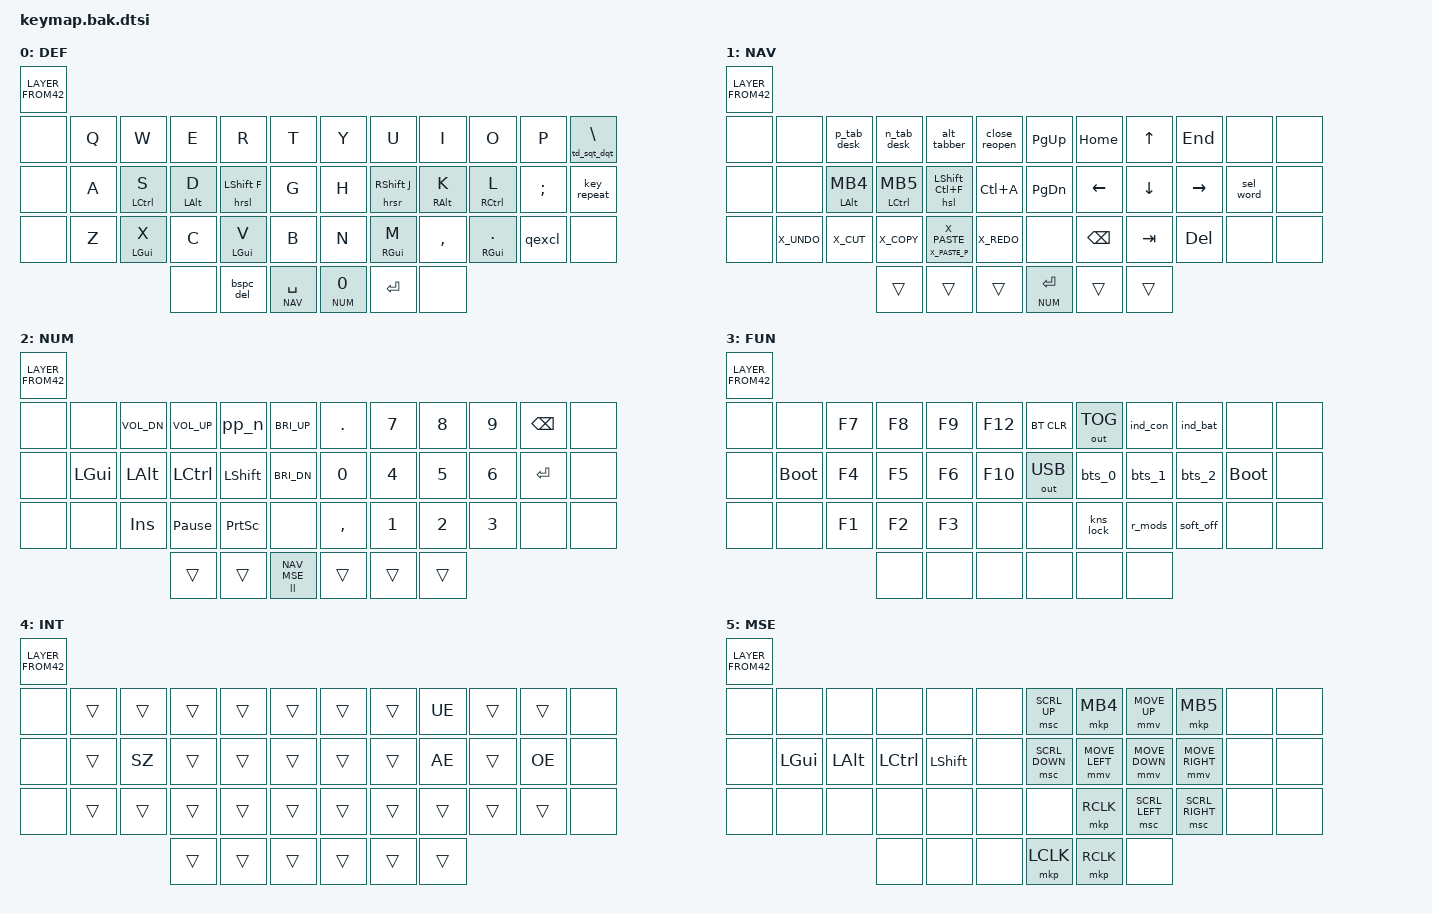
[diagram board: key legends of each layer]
/*
 * Copyright (c) 2020 The ZMK Contributors
 *
 * SPDX-License-Identifier: MIT
 */

#include <dt-bindings/zmk/bt.h>
#include <dt-bindings/zmk/keys.h>
#include <dt-bindings/zmk/mouse.h>
#include <dt-bindings/zmk/outputs.h>

#ifndef KEYMAP_DRAWER
#include "include/keys_de.h"
#endif

#define DEF 0
#define NAV 1
#define NUM 2
#define FUN 3
#define INT 4
#define MSE 5

#define CT(KEY) &mt LC(KEY) KEY

#define MEH     LC(LS(LALT))
#define HYPER   LC(LS(LA(LGUI)))

#define X_REDO   LC(Y)
#define X_PASTE   LC(V)
#define X_PASTE_P LS(LC(V))
#define X_COPY   LC(C)
#define X_CUT   LC(X)
#define X_UNDO   LC(Z)

#include "include/keypos.h"
#include "behaviors.dtsi"
#include "combos.dtsi"
#include "macros.dtsi"
#include "mouse.dtsi"

/ {
    conditional_layers {
        compatible = "zmk,conditional-layers";

        tri_layer  {
            if-layers = <NAV NUM>;
            then-layer = <FUN>;
        };
    };

    keymap {
        compatible = "zmk,keymap";

        default_layer {
            display-name = "DEF";
            bindings = <LAYER_FROM42( \
// ┌─────────────────┬─────────────────┬─────────────────┬─────────────────┬─────────────────┬─────────────────╥─────────────────┬─────────────────┬─────────────────┬─────────────────┬─────────────────┬─────────────────┐
    &none,            &kp Q,            &kp W,            &kp E,            &kp R,            &kp T,            &kp Y,            &kp U,            &kp I,            &kp O,            &kp P,            &td_sqt_dqt,     \
// ├─────────────────┼─────────────────┼─────────────────┼─────────────────┼─────────────────┼─────────────────╫─────────────────┼─────────────────┼─────────────────┼─────────────────┼─────────────────┼─────────────────┤
    &none,            &kp A,            &hrml LCTL S,     &hrml LALT D,     &hrsl LSHIFT F,  &kp G,             &kp H,            &hrsr RSHFT J,    &hrmr RALT K,    &hrmr RCTRL L,   &kp SEMI,         &key_repeat,     \
// ├─────────────────┼─────────────────┼─────────────────┼─────────────────┼─────────────────┼─────────────────╫─────────────────┼─────────────────┼─────────────────┼─────────────────┼─────────────────┼─────────────────┤
    &none,            &kp Z,            &hrml LGUI X,     &kp C,            &hrml LGUI V,    &kp B,             &kp N,            &hrmr RGUI M,     &kp COMMA,        &hrmr RGUI  DOT,    &qexcl,           &none,           \
// └─────────────────┴─────────────────┴─────────────────┼─────────────────┼─────────────────┼─────────────────╫─────────────────┼─────────────────┼─────────────────┼─────────────────┴─────────────────┴─────────────────┘
                                                          &none,            &bspc_del,        &lt NAV SPACE,    &lt_e NUM 0,      &kp RET,          &none            \
//                                                       └─────────────────┴─────────────────┴─────────────────╨─────────────────┴─────────────────┴─────────────────┘
            )>;
        };

        navigation_layer {
            display-name = "NAV";
            bindings = <LAYER_FROM42( \
// ┌─────────────────┬─────────────────┬─────────────────┬─────────────────┬─────────────────┬─────────────────╥─────────────────┬─────────────────┬─────────────────┬─────────────────┬─────────────────┬─────────────────┐
    &none,            &none,            &p_tab_desk,      &n_tab_desk,      &alt_tabber,      &close_reopen,    &kp PG_UP,        &kp HOME,         &kp UP,           &kp END,          &none,            &none,           \
// ├─────────────────┼─────────────────┼─────────────────┼─────────────────┼─────────────────┼─────────────────╫─────────────────┼─────────────────┼─────────────────┼─────────────────┼─────────────────┼─────────────────┤
    &none,            &none,         &hml_m LALT MB4,  &hml_m LCTRL MB5, &hsl LSHFT LC(F), &kp LC(A),        &kp PG_DN,        &kp LEFT,         &kp DOWN,         &kp RIGHT,        &sel_word,        &none,           \
// ├─────────────────┼─────────────────┼─────────────────┼─────────────────┼─────────────────┼─────────────────╫─────────────────┼─────────────────┼─────────────────┼─────────────────┼─────────────────┼─────────────────┤
    &none,            &kp X_UNDO,        &kp X_CUT,        &kp X_COPY,        &mt X_PASTE_P X_PASTE,&kp X_REDO,        &none,            &kp BSPC,         &kp TAB,          &kp DEL,          &none,            &none,           \
// └─────────────────┴─────────────────┴─────────────────┼─────────────────┼─────────────────┼─────────────────╫─────────────────┼─────────────────┼─────────────────┼─────────────────┴─────────────────┴─────────────────┘
                                                          &trans,           &trans,           &trans,           &lt NUM RET,      &trans,           &trans           \
//                                                       └─────────────────┴─────────────────┴─────────────────╨─────────────────┴─────────────────┴─────────────────┘
            )>;
        };

        number_layer {
            display-name = "NUM";
            bindings = <LAYER_FROM42( \
// ┌─────────────────┬─────────────────┬─────────────────┬─────────────────┬─────────────────┬─────────────────╥─────────────────┬─────────────────┬─────────────────┬─────────────────┬─────────────────┬─────────────────┐
    &none,            &none,            &kp C_VOL_DN,     &kp C_VOL_UP,     &pp_n,            &kp C_BRI_UP,     &kp DOT,       &kp N7,           &kp N8,           &kp N9,           &kp BSPC,         &none,           \
// ├─────────────────┼─────────────────┼─────────────────┼─────────────────┼─────────────────┼─────────────────╫─────────────────┼─────────────────┼─────────────────┼─────────────────┼─────────────────┼─────────────────┤
    &none,            &kp LGUI,         &kp LALT,         &kp LCTRL,        &kp LSHFT,        &kp C_BRI_DN,     &kp N0,           &kp N4,           &kp N5,           &kp N6,           &kp RET,          &none,           \
// ├─────────────────┼─────────────────┼─────────────────┼─────────────────┼─────────────────┼─────────────────╫─────────────────┼─────────────────┼─────────────────┼─────────────────┼─────────────────┼─────────────────┤
    &none,            &none,            &kp INS,          &kp PAUSE_BREAK,  &kp PSCRN,        &none,            &kp COMMA,     &kp N1,           &kp N2,           &kp N3,           &none,            &none,           \
// └─────────────────┴─────────────────┴─────────────────┼─────────────────┼─────────────────┼─────────────────╫─────────────────┼─────────────────┼─────────────────┼─────────────────┴─────────────────┴─────────────────┘
                                                          &trans,           &trans,           &ll  NAV MSE,     &trans,           &trans,           &trans           \
//                                                       └─────────────────┴─────────────────┴─────────────────╨─────────────────┴─────────────────┴─────────────────┘
            )>;
        };

        function_layer {
            display-name = "FUN";
            bindings = <LAYER_FROM42( \
// ┌─────────────────┬─────────────────┬─────────────────┬─────────────────┬─────────────────┬─────────────────╥─────────────────┬─────────────────┬─────────────────┬─────────────────┬─────────────────┬─────────────────┐
    &none,            &none,            &kp F7,           &kp F8,           &kp F9,           &kp F12,          &bt BT_CLR,       &out OUT_TOG,     &ind_con,         &ind_bat,         &none,            &none,           \
// ├─────────────────┼─────────────────┼─────────────────┼─────────────────┼─────────────────┼─────────────────╫─────────────────┼─────────────────┼─────────────────┼─────────────────┼─────────────────┼─────────────────┤
    &none,            &bootloader,      &kp F4,           &kp F5,           &kp F6,           &kp F10,          &out OUT_USB,     &bts_0,           &bts_1,           &bts_2,           &bootloader,      &none,           \
// ├─────────────────┼─────────────────┼─────────────────┼─────────────────┼─────────────────┼─────────────────╫─────────────────┼─────────────────┼─────────────────┼─────────────────┼─────────────────┼─────────────────┤
    &none,            &none,            &kp F1,           &kp F2,           &kp F3,           &none,            &none,            &kns_lock,        &r_mods,          &soft_off,        &none,            &none,           \
// └─────────────────┴─────────────────┴─────────────────┼─────────────────┼─────────────────┼─────────────────╫─────────────────┼─────────────────┼─────────────────┼─────────────────┴─────────────────┴─────────────────┘
                                                          &none,            &none,            &none,            &none,            &none,            &none            \
//                                                       └─────────────────┴─────────────────┴─────────────────╨─────────────────┴─────────────────┴─────────────────┘
            )>;
        };

        international_layer {
            display-name = "INT";
            bindings = <LAYER_FROM42( \
// ┌─────────────────┬─────────────────┬─────────────────┬─────────────────┬─────────────────┬─────────────────╥─────────────────┬─────────────────┬─────────────────┬─────────────────┬─────────────────┬─────────────────┐
    &none,            &trans,           &trans,           &trans,           &trans,               &trans,       &trans,           &trans,           &kp UE,        &trans,           &trans,           &none,           \
// ├─────────────────┼─────────────────┼─────────────────┼─────────────────┼─────────────────┼─────────────────╫─────────────────┼─────────────────┼─────────────────┼─────────────────┼─────────────────┼─────────────────┤
    &none,            &trans,           &kp SZ,        &trans,           &trans,               &trans,       &trans,           &trans,           &kp AE,        &trans,           &kp OE,        &none,           \
// ├─────────────────┼─────────────────┼─────────────────┼─────────────────┼─────────────────┼─────────────────╫─────────────────┼─────────────────┼─────────────────┼─────────────────┼─────────────────┼─────────────────┤
    &none,            &trans,           &trans,           &trans,           &trans,               &trans,       &trans,           &trans,           &trans,           &trans,           &trans,           &none,           \
// └─────────────────┴─────────────────┴─────────────────┼─────────────────┼─────────────────┼─────────────────╫─────────────────┼─────────────────┼─────────────────┼─────────────────┴─────────────────┴─────────────────┘
                                                          &trans,           &trans,             &trans,         &trans,           &trans,           &trans           \
//                                                       └─────────────────┴─────────────────┴─────────────────╨─────────────────┴─────────────────┴─────────────────┘

            )>;
        };

        mouse_layer {
            display-name = "MSE";
            bindings = <LAYER_FROM42( \
// ┌─────────────────┬─────────────────┬─────────────────┬─────────────────┬─────────────────┬─────────────────╥─────────────────┬─────────────────┬─────────────────┬─────────────────┬─────────────────┬─────────────────┐
    &none,            &none,            &none,            &none,            &none,            &none,            &msc SCRL_UP,     &mkp MB4,         &mmv MOVE_UP,     &mkp MB5,         &none,            &none,           \
// ├─────────────────┼─────────────────┼─────────────────┼─────────────────┼─────────────────┼─────────────────╫─────────────────┼─────────────────┼─────────────────┼─────────────────┼─────────────────┼─────────────────┤
    &none,            &kp LGUI,         &kp LALT,         &kp LCTRL,        &kp LSHFT,        &none,            &msc SCRL_DOWN,   &mmv MOVE_LEFT,   &mmv MOVE_DOWN,   &mmv MOVE_RIGHT,  &none,            &none,           \
// ├─────────────────┼─────────────────┼─────────────────┼─────────────────┼─────────────────┼─────────────────╫─────────────────┼─────────────────┼─────────────────┼─────────────────┼─────────────────┼─────────────────┤
    &none,            &none,            &none,            &none,            &none,            &none,            &none,            &mkp RCLK,        &msc SCRL_LEFT,   &msc SCRL_RIGHT,  &none,            &none,           \
// └─────────────────┴─────────────────┴─────────────────┼─────────────────┼─────────────────┼─────────────────╫─────────────────┼─────────────────┼─────────────────┼─────────────────┴─────────────────┴─────────────────┘
                                                          &none,            &none,            &none,            &mkp LCLK,        &mkp RCLK,        &none            \
//                                                       └─────────────────┴─────────────────┴─────────────────╨─────────────────┴─────────────────┴─────────────────┘
            )>;
        };

        extra1 {
            status = "reserved";
        };

        extra2 {
            status = "reserved";
        };
    };
};
